# haltium_secure register map
Vendor: Nordic Semiconductor; Series: nRFHaltium; File version: 1
CPU: CM33 r0p4, little endian, MPU, FPU, 3 interrupt priority bits, 480 interrupts
Registers are 32-bit, read-write, reset 0x0 unless marked. A register's access mark holds for its fields unless they carry their own. Offsets are from the block's base; [hi:lo] are bit positions; lines under a group give offsets from that group; {n}, {i} and the like mark numbered series; 'fields as' and 'values as' point back to an identical list.

## CPUCONF_NS — CPU Configuration 0
Base 0x41011000
Same registers: CPUCONF_S 0x51011000
0x00 TASKS_ERASECACHE wo — Erase the caches used by the CPU.
  [0] TASKS_ERASECACHE
    1=Trigger task
0x500 INITSVTOR — Initial value of the secure VTOR (Vector Table Offset Register) after CPU reset.
  [31:0] INITSVTOR — Initial value of the VTOR.
0x504 INITNSVTOR — Initial value of the non-secure VTOR (Vector Table Offset Register).
  [31:0] INITNSVTOR — Initial value of the VTOR.
0x508 CPUSTART — Enable for starting the CPU
  [0] EN — Enable to start the CPU.
    0=Stopped (CPU stopped.); 1=Started (CPU started.)
0x50C CPUWAIT — Enable for the CPU wait.
  [0] EN — Enable to the CPU wait.
    0=Disabled (CPU is not waiting.); 1=Enabled (CPU is waiting.)

## MUTEX_NS — MUTEX 0
Base 0x41017000
Same registers: GLOBAL_MUTEX120_NS 0x4F8D2000, GLOBAL_MUTEX130_NS 0x4F927000, MUTEX_S 0x51017000
{0x400+4i} MUTEX[{i}] (i=0..15) — Description collection: Mutex register
  [0] MUTEX — Mutex register n
    0=Unlocked (Mutex n is in unlocked state); 1=Locked (Mutex n is in locked state)

## BELLBOARD_NS — BELLBOARD APB registers 0
Base 0x4F099000
Same registers: BELLBOARD_S 0x5F099000
{0x0+4i} TASKS_TRIGGER[{i}] (i=0..31) wo — Description collection: Task TRIGGER[n]
  [0] TASKS_TRIGGER — Task TRIGGER[n]
    1=Trigger task
{0x100+4i} EVENTS_TRIGGERED[{i}] (i=0..31) — Description collection: Event TRIGGERED[n]
  [0] EVENTS_TRIGGERED — Event TRIGGERED[n]
    0=NotGenerated (Event not generated); 1=Generated (Event generated)
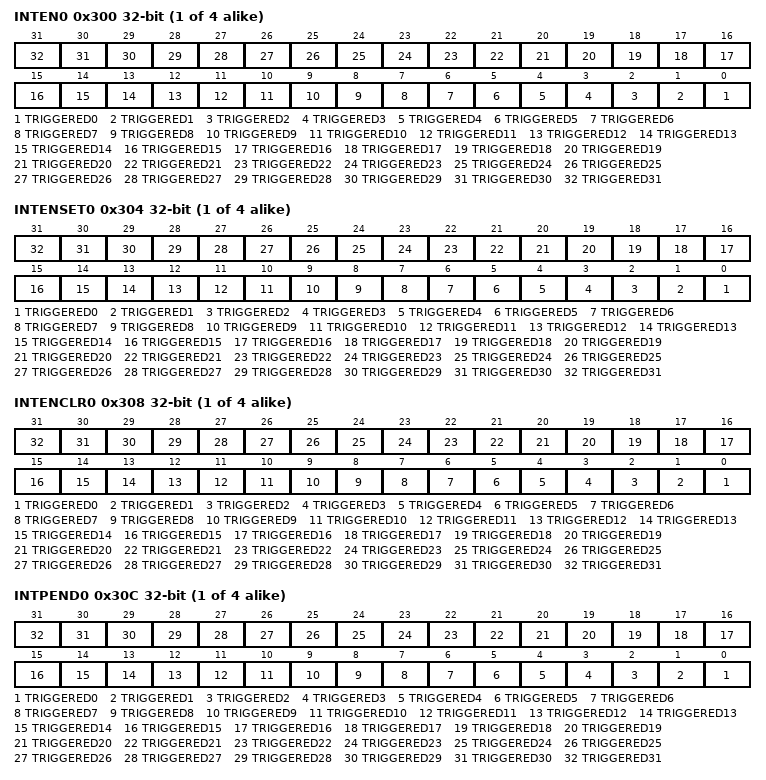
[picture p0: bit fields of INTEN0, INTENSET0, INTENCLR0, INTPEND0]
{0x300+0x10*i} INTEN{i} (i=0..3) — Enable or disable interrupt
  [all] fields
    0=Disabled; 1=Enabled
  [n] TRIGGERED{n} (n=0..31) — Enable or disable interrupt for event TRIGGERED[{n}]
{0x304+0x10*i} INTENSET{i} (i=0..3) — Enable interrupt
  [all] fields
    on read: 0=Disabled (Read: Disabled); 1=Enabled (Read: Enabled) | on write: 1=Set (Enable)
  [n] TRIGGERED{n} (n=0..31) — Write '1' to enable interrupt for event TRIGGERED[{n}]
{0x308+0x10*i} INTENCLR{i} (i=0..3) — Disable interrupt
  [all] fields
    on read: 0=Disabled (Read: Disabled); 1=Enabled (Read: Enabled) | on write: 1=Clear (Disable)
  [n] TRIGGERED{n} (n=0..31) — Write '1' to disable interrupt for event TRIGGERED[{n}]
{0x30C+0x10*i} INTPEND{i} ro (i=0..3) — Pending interrupts
  [all] fields
    on read: 0=NotPending (Read: Not pending); 1=Pending (Read: Pending)
  [n] TRIGGERED{n} (n=0..31) — Read pending status of interrupt for event TRIGGERED[{n}]

## GLOBAL_I3C120_NS — I3C 0
Base 0x4F8D3000
Same registers: GLOBAL_I3C121_NS 0x4F8D4000, GLOBAL_I3C120_S 0x5F8D3000, GLOBAL_I3C121_S 0x5F8D4000
0x100 EVENTS_CORE — Event indicating that interrupt triggered at I3C core
  [0] EVENTS_CORE
    0=NotGenerated (Event not generated); 1=Generated (Event generated)
0x104 EVENTS_DMA — Event indicating that interrupt triggered at I3C DMA
  [0] EVENTS_DMA
    values as EVENTS_CORE.EVENTS_CORE
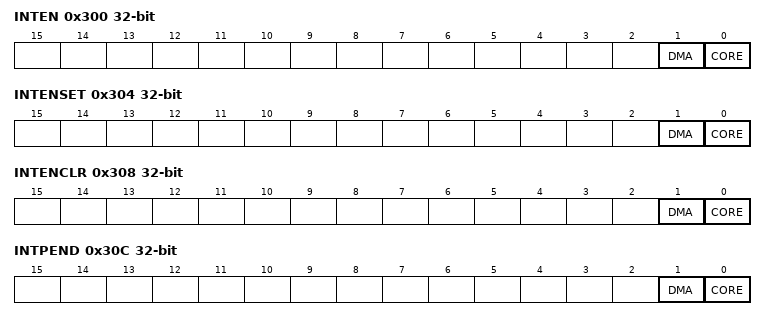
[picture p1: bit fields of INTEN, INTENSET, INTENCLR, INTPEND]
0x300 INTEN — Enable or disable interrupt
  [1] DMA — Enable or disable interrupt for event DMA
    0=Disabled; 1=Enabled
  [0] CORE — Enable or disable interrupt for event CORE
    0=Disabled; 1=Enabled
0x304 INTENSET — Enable interrupt
  [1] DMA — Write '1' to enable interrupt for event DMA
    on read: 0=Disabled (Read: Disabled); 1=Enabled (Read: Enabled) | on write: 1=Set (Enable)
  [0] CORE — Write '1' to enable interrupt for event CORE
    values as DMA
0x308 INTENCLR — Disable interrupt
  [1] DMA — Write '1' to disable interrupt for event DMA
    on read: 0=Disabled (Read: Disabled); 1=Enabled (Read: Enabled) | on write: 1=Clear (Disable)
  [0] CORE — Write '1' to disable interrupt for event CORE
    values as DMA
0x30C INTPEND ro — Pending interrupts
  [1] DMA — Read pending status of interrupt for event DMA
    on read: 0=NotPending (Read: Not pending); 1=Pending (Read: Pending)
  [0] CORE — Read pending status of interrupt for event CORE
    values as DMA
0x400 ENABLE — Enable I3C peripheral.
  [0] EN — Enable
    0=Disabled (I3C peripheral disabled.); 1=Enabled (I3C peripheral enabled.)
0x404 CDR group — Unspecified
  0x00 STARTOFFSET — Start offset of recovered clock
    [15:0] VAL — Value
  0x04 MAXCYCLERATIO — Maximum cycle ratio between SDA/SCL and CDR (clock and data recovery) clock
    [15:0] VAL — Value
  0x08 MAXSKEW — Maximum skew between SCL and SCL in CDR clock cycles
    [7:0] VAL — Value
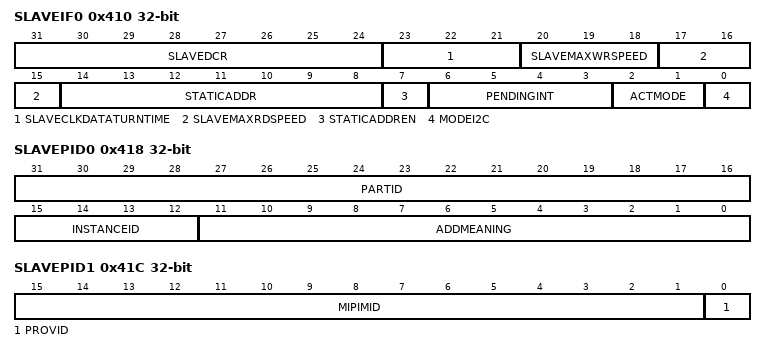
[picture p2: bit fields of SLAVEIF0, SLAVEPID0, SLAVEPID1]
0x410 SLAVEIF0 — I3C slave interface 0
  [31:24] SLAVEDCR — Device Characteristic Register value
  [23:21] SLAVECLKDATATURNTIME — Slave maximum clock data turnaround time
  [20:18] SLAVEMAXWRSPEED — Slave maximum write write rate
  [17:15] SLAVEMAXRDSPEED — Slave maximum read data rate
  [14:8] STATICADDR — Slave static address
  [7] STATICADDREN — Slave static address valid
    0=DISABLED (Unspecified); 1=ENABLED (Unspecified)
  [6:3] PENDINGINT — Pending interrupt information for GETSTATUS CCC
  [2:1] ACTMODE — Slave activity mode for GETSTATUS CCC
  [0] MODEI2C — I2C or I3C mode select signal
    0=DISABLED (Unspecified); 1=ENABLED (Unspecified)
0x414 SLAVEIF1 — I3C slave interface 1
  [0] WAKEUP — Slave wakeup signal
    0=DISABLED (Unspecified); 1=ENABLED (Unspecified)
0x418 SLAVEPID0 — Slave Device Provisioned ID 0
  [31:16] PARTID
  [15:12] INSTANCEID
  [11:0] ADDMEANING — Additional Meaning
0x41C SLAVEPID1 — Slave Device Provisioned ID 1
  [15:1] MIPIMID — MIPI Manufacturer ID
  [0] PROVID — Provisional ID Type Selector
0x420 KEEPSDA — Enable or disable the SDA high-keeper used for Master-to-Slave and Slave-to-Master bus hand-off.
  [0] ENABLE — Enable or disable the SDA high-keeper
    0=Disabled (High-keeper disabled.); 1=Enabled (High-keeper enabled.)
0x424 KEEPSCL — Enable or disable the SCL high-keeper used for Master-to-Slave and Slave-to-Master bus hand-off.
  [0] ENABLE — Enable or disable the SCL high-keeper
    values as KEEPSDA.ENABLE
